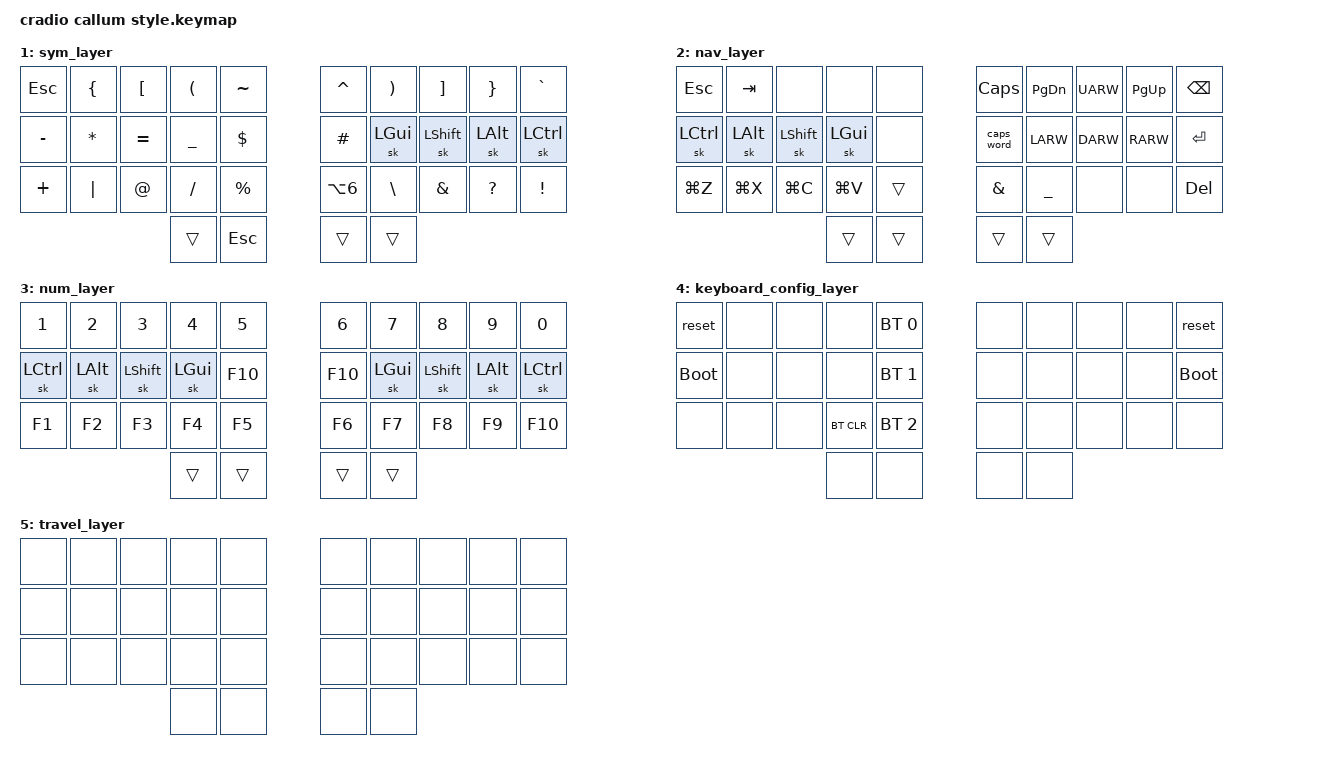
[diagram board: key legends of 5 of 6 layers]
// Copyright (c) 2022 The ZMK Contributors
// SPDX-License-Identifier: MIT

#include <behaviors.dtsi>
#include <dt-bindings/zmk/keys.h>
#include <dt-bindings/zmk/bt.h>

// Home row mods macro
#define HRML(k1,k2,k3,k4) &ht LCTRL k1  &ht LALT k2  &ht LSHFT k3  &ht LGUI k4
#define HRMR(k1,k2,k3,k4) &ht RGUI k1  &ht RSHFT k2 &ht RALT k3  &ht RCTRL k4

/ {
    behaviors {
        ht: hold_tap {
            label = "hold_tap";
            compatible = "zmk,behavior-hold-tap";
            #binding-cells = <2>;
            flavor = "tap-preferred";
            tapping-term-ms = <220>;
            quick-tap-ms = <150>;
            global-quick-tap;
            bindings = <&kp>, <&kp>;
        };
    };

    conditional_layers {
        compatible = "zmk,conditional-layers";
        tri_layer {
            if-layers = <1 2>;
            then-layer = <3>;
        };
    };

    keymap {
        compatible = "zmk,keymap";
        default_layer {
            bindings = <
        //╭──────────┬──────────┬──────────┬──────────┬──────────╮   ╭──────────┬──────────┬──────────┬──────────┬──────────╮
        //│  Q       │  W       │  E       │  R       │  T       │   │  Y       │  U       │  I       │  O       │  P       │
            &kp Q      &kp W      &kp E      &kp R      &kp T          &kp Y      &kp U      &kp I      &kp O      &kp P
        //├──────────┼──────────┼──────────┼──────────┼──────────┤   ├──────────┼──────────┼──────────┼──────────┼──────────┤
        //│  A       │  S       │  D       │  F       │  G       │   │  H       │  J       │  K       │  L       │ ' "      │
            HRML(A,        S,         D,         F)     &kp G          &kp H      HRMR(J,        K,         L,        SQT)
        //├──────────┼──────────┼──────────┼──────────┼──────────┤   ├──────────┼──────────┼──────────┼──────────┼──────────┤
        //│  Z       │  X       │  C       │  V       │  B       │   │  N       │  M       │ , <      │ . >      │ ; :      │
            &kp Z      &kp X      &kp C      &kp V      &kp B          &kp N      &kp M      &kp COMMA  &kp DOT    &kp SEMI
        //╰──────────┴──────────┴──────────┼──────────┼──────────┤   ├──────────┼──────────┼──────────┴──────────┴──────────╯
                                            &lt 2 TAB   &kp ENTER     &kp SPACE  &lt 1 BSPC
        //                                 ╰──────────┴──────────╯   ╰──────────┴──────────╯
            >;
        };

        sym_layer {
            bindings = <
        //╭──────────┬──────────┬──────────┬──────────┬──────────╮   ╭──────────┬──────────┬──────────┬──────────┬──────────╮
        //│ ESC      │  {       │  [       │  (       │ ~        │   │ ^        │ )        │ ]        │ }        │  `       │
            &kp ESC    &kp LBRC   &kp LBKT   &kp LPAR   &kp TILDE      &kp CARET  &kp RPAR   &kp RBKT   &kp RBRC   &kp GRAVE
        //├──────────┼──────────┼──────────┼──────────┼──────────┤   ├──────────┼──────────┼──────────┼──────────┼──────────┤
        //│ -        │ *        │ =        │ _        │ $        │   │ #        │ CMD      │ SHIFT    │ ALT      │ CTRL     │
            &kp MINUS  &kp ASTRK  &kp EQUAL  &kp UNDER  &kp DLLR       &kp HASH   &sk LGUI   &sk LSHFT  &sk LALT   &sk LCTRL
        //├──────────┼──────────┼──────────┼──────────┼──────────┤   ├──────────┼──────────┼──────────┼──────────┼──────────┤
        //│ +        │ |        │  @       │  /       │  %       │   │ §        │ \        │ &        │ ?        │ !        │
            &kp PLUS   &kp PIPE   &kp AT     &kp FSLH   &kp PRCNT      &kp LA(N6) &kp BSLH   &kp AMPS   &kp QMARK  &kp EXCL
        //╰──────────┴──────────┴──────────┼──────────┼──────────┤   ├──────────┼──────────┼──────────┴──────────┴──────────╯
                                             &trans     &kp ESC        &trans     &trans
        //                                 ╰──────────┴──────────╯   ╰──────────┴──────────╯
            >;
        };

        nav_layer {
            bindings = <
        //╭──────────┬──────────┬──────────┬──────────┬──────────╮   ╭──────────┬──────────┬──────────┬──────────┬──────────╮
        //│ GESC     │  TAB     │          │          │          │   │ CAPS LOCK│ PG DOWN  │ UP       │ PG UP    │ BACKSPACE│
            &kp ESC     &kp TAB   &none      &none      &none          &kp CAPS   &kp PG_DN  &kp UARW   &kp PG_UP  &kp BSPC
        //├──────────┼──────────┼──────────┼──────────┼──────────┤   ├──────────┼──────────┼──────────┼──────────┼──────────┤
        //│ CTRL     │ ALT      │ SHIFT    │ CMD      │          │   │ CAPSWORD │ LEFT     │ DOWN     │ RIGHT    │ ENTER    │
            &sk LCTRL  &sk LALT   &sk LSHFT  &sk LGUI   &none         &caps_word  &kp LARW   &kp DARW   &kp RARW   &kp ENTER
        //├──────────┼──────────┼──────────┼──────────┼──────────┤   ├──────────┼──────────┼──────────┼──────────┼──────────┤
        //│ UNDO     │ CUT      │ COPY     │ PASTE    │          │   │ BACK     │ FORWARD  │          │          │ DELETE   │
            &kp LG(Z)  &kp LG(X)  &kp LG(C)  &kp LG(V)  &trans         &kp AMPS   &kp UNDER  &none      &none      &kp DEL
        //╰──────────┴──────────┴──────────┼──────────┼──────────┤   ├──────────┼──────────┼──────────┴──────────┴──────────╯
                                             &trans     &trans         &trans     &trans
        //                                 ╰──────────┴──────────╯   ╰──────────┴──────────╯
            >;
        };

        num_layer {
            bindings = <
        //╭──────────┬──────────┬──────────┬──────────┬──────────╮   ╭──────────┬──────────┬──────────┬──────────┬──────────╮
        //│ 1        │ 2        │ 3        │ 4        │ 5        │   │ 6        │ 7        │ 8        │ 9        │ 0        │
            &kp N1     &kp N2     &kp N3     &kp N4    &kp N5          &kp N6     &kp N7     &kp N8     &kp N9     &kp N0
        //├──────────┼──────────┼──────────┼──────────┼──────────┤   ├──────────┼──────────┼──────────┼──────────┼──────────┤
        //│ CTRL     │ ALT      │ SHIFT    │ CMD      │ F11      │   │ F12      │ CMD      │ SHIFT    │ ALT      │ CTRL     │
            &sk LCTRL  &sk LALT   &sk LSHFT  &sk LGUI   &kp F10        &kp F10    &sk LGUI   &sk LSHFT  &sk LALT   &sk LCTRL
        //├──────────┼──────────┼──────────┼──────────┼──────────┤   ├──────────┼──────────┼──────────┼──────────┼──────────┤
        //│ F1       │ F2       │ F3       │ F4       │ F5       │   │ F6       │ F7       │ F8       │ F9       │ F10      │
            &kp F1     &kp F2     &kp F3     &kp F4    &kp F5          &kp F6     &kp F7     &kp F8     &kp F9     &kp F10
        //╰──────────┴──────────┴──────────┼──────────┼──────────┤   ├──────────┼──────────┼──────────┴──────────┴──────────╯
                                             &trans     &trans         &trans     &trans
        //                                 ╰──────────┴──────────╯   ╰──────────┴──────────╯
            >;
        };
        
        keyboard_config_layer {
            bindings = <
        //╭──────────┬──────────┬──────────┬──────────┬──────────╮   ╭──────────┬──────────┬──────────┬──────────┬──────────╮
        //│ RESET    │          │          │          │PROFILE 0 │   │          │          │          │          │  RESET   │
            &reset     &none      &none      &none     &bt BT_SEL 0    &none      &none      &none      &none       &reset
        //├──────────┼──────────┼──────────┼──────────┼──────────┤   ├──────────┼──────────┼──────────┼──────────┼──────────┤
        //│BOOTLOADER│          │          │          │PROFILE 1 │   │          │          │          │          │BOOTLOADER│
          &bootloader  &none      &none      &none     &bt BT_SEL 1    &none      &none      &none      &none     &bootloader
        //├──────────┼──────────┼──────────┼──────────┼──────────┤   ├──────────┼──────────┼──────────┼──────────┼──────────┤
        //│          │          │          │ CLEAR BT │PROFILE 2 │   │          │          │          │          │          │
            &none      &none      &none     &bt BT_CLR &bt BT_SEL 2    &none      &none      &none      &none      &none 
        //╰──────────┴──────────┴──────────┼──────────┼──────────┤   ├──────────┼──────────┼──────────┴──────────┴──────────╯
                                             &none      &none          &none      &none 
        //                                 ╰──────────┴──────────╯   ╰──────────┴──────────╯
            >;
        };
        travel_layer {
            bindings = <
        //╭──────────┬──────────┬──────────┬──────────┬──────────╮   ╭──────────┬──────────┬──────────┬──────────┬──────────╮
        //│          │          │          │          │          │   │          │          │          │          │          │
            &none       &none     &none      &none     &none           &none      &none      &none      &none      &none
        //├──────────┼──────────┼──────────┼──────────┼──────────┤   ├──────────┼──────────┼──────────┼──────────┼──────────┤
        //│          │          │          │          │          │   │          │          │          │          │          │
            &none       &none     &none      &none     &none           &none      &none      &none      &none      &none
        //├──────────┼──────────┼──────────┼──────────┼──────────┤   ├──────────┼──────────┼──────────┼──────────┼──────────┤
        //│          │          │          │          │          │   │          │          │          │          │          │
            &none       &none     &none      &none     &none           &none      &none      &none      &none      &none
        //╰──────────┴──────────┴──────────┼──────────┼──────────┤   ├──────────┼──────────┼──────────┴──────────┴──────────╯
                                             &none      &none          &none      &none
        //                                 ╰──────────┴──────────╯   ╰──────────┴──────────╯
            >;
        };
    };
};
